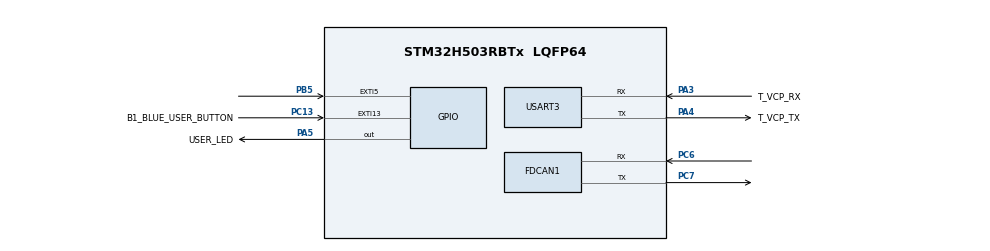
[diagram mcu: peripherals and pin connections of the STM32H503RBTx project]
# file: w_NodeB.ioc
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BOOTPATH.BootPathName=LEGACY
BOOTPATH.UserSelectedBootPath=LEGACY
FDCAN1.CalculateBaudRateNominal=500000
FDCAN1.CalculateTimeBitNominal=2000
FDCAN1.CalculateTimeQuantumNominal=125.0
FDCAN1.NominalPrescaler=25
FDCAN1.NominalTimeSeg1=13
FDCAN1.NominalTimeSeg2=2
Mcu.Family=STM32H5
Mcu.Name=STM32H503RBTx
Mcu.Package=LQFP64
NVIC.EXTI13_IRQn=true\:0\:0\:false\:false\:true\:true\:true\:true
NVIC.EXTI5_IRQn=true\:0\:0\:false\:false\:true\:true\:true\:true
NVIC.FDCAN1_IT0_IRQn=true\:0\:0\:false\:false\:true\:true\:true\:true
NVIC.PriorityGroup=NVIC_PRIORITYGROUP_4
NVIC.USART3_IRQn=true\:0\:0\:false\:false\:true\:true\:true\:true
PA3.GPIO_Label=T_VCP_RX
PA3.Mode=Asynchronous
PA3.Signal=USART3_RX
PA4.GPIO_Label=T_VCP_TX
PA4.Mode=Asynchronous
PA4.Signal=USART3_TX
PA5.GPIO_Label=USER_LED
PA5.Signal=GPIO_Output
PB5.Signal=GPXTI5
PC13.GPIO_Label=B1_BLUE_USER_BUTTON
PC13.Signal=GPXTI13
PC6.Mode=FDCAN_Activate
PC6.Signal=FDCAN1_RX
PC7.Mode=FDCAN_Activate
PC7.Signal=FDCAN1_TX
PH0-OSC_IN(PH0).Mode=HSE-External-Oscillator
PH0-OSC_IN(PH0).Signal=RCC_OSC_IN
PH1-OSC_OUT(PH1).Mode=HSE-External-Oscillator
PH1-OSC_OUT(PH1).Signal=RCC_OSC_OUT
ProjectManager.HeapSize=0x200
ProjectManager.StackSize=0x400
ProjectManager.TargetToolchain=STM32CubeIDE
RCC.ADCFreq_Value=200000000
RCC.AHBFreq_Value=200000000
RCC.APB1Freq_Value=200000000
RCC.APB1TimFreq_Value=200000000
RCC.APB2Freq_Value=200000000
RCC.APB2TimFreq_Value=200000000
RCC.APB3Freq_Value=200000000
RCC.CSI_VALUE=4000000
RCC.CortexFreq_Value=200000000
RCC.EPOD_VALUE=24000000
RCC.FDCANClockSelection=RCC_FDCANCLKSOURCE_PLL1Q
RCC.HCLKFreq_Value=200000000
RCC.HSE_VALUE=24000000
RCC.HSI48_VALUE=48000000
RCC.HSIDiv=RCC_HSI_DIV1
RCC.HSI_VALUE=64000000
RCC.LSE_VALUE=32768
RCC.LSIRC_VALUE=32000
RCC.PLLFRACN=0
RCC.PLLM=3
RCC.PLLN=50
RCC.PLLSourceVirtual=RCC_PLL1_SOURCE_HSE
RCC.SYSCLKFreq_VALUE=200000000
RCC.SYSCLKSource=RCC_SYSCLKSOURCE_PLLCLK
RCC.USBFreq_Value=48000000
RCC.VCOOutputFreq_Value=400000000
USART3.VirtualMode-Asynchronous=VM_ASYNC
VP_BOOTPATH_VS_BOOTPATH.Mode=BP_Activate
VP_CORTEX_M33_NS_VS_Hclk.Mode=Hclk_Mode
VP_MEMORYMAP_VS_MEMORYMAP.Mode=CurAppReg
VP_PWR_VS_DBSignals.Mode=DisableDeadBatterySignals
VP_PWR_VS_LPOM.Mode=PowerOptimisation
VP_PWR_VS_SECSignals.Mode=Security/Privilege
board=NUCLEO-H503RB

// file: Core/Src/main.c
#include "main.h"
#include <stdio.h>

FDCAN_HandleTypeDef hfdcan1;
UART_HandleTypeDef huart3;
static void MX_FDCAN1_Init(void);
void SetFilter(uint16_t ID ,uint16_t msk);
void Test_Priority();
void TX_Send_CAN();
void Print_CAN_Error();
void Check_CAN_ErrorCnt();
void Check_CAN_Protocol_Status();
/* declared variable -----------------------------------------------*/
volatile uint8_t counter = 0;
volatile uint8_t flag = 0;
volatile uint8_t tx_complete_flag = 0;
typedef struct{
	FDCAN_TxHeaderTypeDef   TxHeader;
	FDCAN_RxHeaderTypeDef   RxHeader;
	uint32_t msgID;
	uint8_t dataTx[8];
	uint8_t dataRx[8];
} CAN_SET;

CAN_SET CAN_Payload;

int main(void)
{
  /* MCU Configuration--------------------------------------------------------*/
   HAL_Init();
  /* Configure the system clock */
  SystemClock_Config();
  /* Initialize all configured peripherals */
  MX_GPIO_Init();
  MX_FDCAN1_Init();
  MX_USART3_UART_Init();

  //CAN_Payload.dataTx[0] = 0x0;
  for(uint8_t i = 0 ; i < 8 ;i++){
  	  CAN_Payload.dataTx[i] = 0xFF;
    }

  while (1)
  {
	  if (flag == 1){
		  HAL_Delay(1);
		  Print_CAN_Error();
		  Check_CAN_ErrorCnt();
		  Check_CAN_Protocol_Status();
		  flag = 0;
	  }
//	  if (tx_complete_flag == 1)
//	     {
//	         tx_complete_flag = 0;
//
//	         Print_CAN_Error();
//	         Check_CAN_ErrorCnt();
//	         Check_CAN_Protocol_Status();
//	     }
  }
}

static void MX_FDCAN1_Init(void)
{

  hfdcan1.Instance = FDCAN1;
  hfdcan1.Init.ClockDivider = FDCAN_CLOCK_DIV1;
  hfdcan1.Init.FrameFormat = FDCAN_FRAME_CLASSIC;
  hfdcan1.Init.Mode = FDCAN_MODE_NORMAL;
  hfdcan1.Init.AutoRetransmission = DISABLE;
  hfdcan1.Init.TransmitPause = DISABLE;
  hfdcan1.Init.ProtocolException = DISABLE;
  hfdcan1.Init.NominalPrescaler = 25;
  hfdcan1.Init.NominalSyncJumpWidth = 1;
  hfdcan1.Init.NominalTimeSeg1 = 13;
  hfdcan1.Init.NominalTimeSeg2 = 2;
  hfdcan1.Init.DataPrescaler = 1;
  hfdcan1.Init.DataSyncJumpWidth = 1;
  hfdcan1.Init.DataTimeSeg1 = 1;
  hfdcan1.Init.DataTimeSeg2 = 1;
  hfdcan1.Init.StdFiltersNbr = 1;
  hfdcan1.Init.ExtFiltersNbr = 0;
  hfdcan1.Init.TxFifoQueueMode = FDCAN_TX_FIFO_OPERATION;
  if (HAL_FDCAN_Init(&hfdcan1) != HAL_OK)
  {
    Error_Handler();
  }
  /* USER CODE BEGIN FDCAN1_Init 2 */
  if (HAL_FDCAN_Start(&hfdcan1) != HAL_OK) {
  	 /* Notification Error */
  	Error_Handler();
  }
  if (HAL_FDCAN_ActivateNotification(&hfdcan1, FDCAN_IT_RX_FIFO0_NEW_MESSAGE, 0) != HAL_OK)
  {
	/* Notification Error */
	Error_Handler();
  }
 // HAL_FDCAN_ActivateNotification(&hfdcan1, FDCAN_IT_TX_COMPLETE, 0);
  /* USER CODE END FDCAN1_Init 2 */
}

void Test_Ack(){
	CAN_Payload.msgID = 0x10F;
	//CAN_Payload.msgID = 0x000;
	TX_Send_CAN();
}

void TX_Send_CAN(){

    /* ----- Prepare CAN data --------------------------------------- */
    CAN_Payload.TxHeader.IdType = FDCAN_STANDARD_ID;
    CAN_Payload.TxHeader.Identifier = CAN_Payload.msgID; //CAN_Payload.msgID
    CAN_Payload.TxHeader.TxFrameType = FDCAN_DATA_FRAME;
    CAN_Payload.TxHeader.DataLength = FDCAN_DLC_BYTES_8;        // 8-byte payloaD
    CAN_Payload.TxHeader.ErrorStateIndicator = FDCAN_ESI_ACTIVE;
    CAN_Payload.TxHeader.BitRateSwitch = FDCAN_BRS_OFF;         // Disable BRS
    CAN_Payload.TxHeader.FDFormat = FDCAN_CLASSIC_CAN;          // Use Classical CAN frame
    CAN_Payload.TxHeader.TxEventFifoControl = FDCAN_NO_TX_EVENTS;
    CAN_Payload.TxHeader.MessageMarker = 0;

    CAN_Payload.dataTx[0] ^= 1;

    if (HAL_FDCAN_AddMessageToTxFifoQ(&hfdcan1, &CAN_Payload.TxHeader,CAN_Payload.dataTx)!= HAL_OK)
    {
      /*do not thing */
    }

}

void HAL_GPIO_EXTI_Falling_Callback(uint16_t GPIO_Pin){

	if(GPIO_Pin == GPIO_PIN_5) {
		flag = 1;
		GPIOA->ODR &= ~(1<<5);
	}

	if(GPIO_Pin == B1_BLUE_USER_BUTTON_Pin){
		Test_Ack();
		flag = 1;
		GPIOA->ODR |= (1<<5);
	}
}

void HAL_FDCAN_RxFifo0Callback(FDCAN_HandleTypeDef *hfdcan, uint32_t RxFifo0ITs)
{
	if((RxFifo0ITs & FDCAN_IT_RX_FIFO0_NEW_MESSAGE) != RESET)
	{
		/* Retreive Rx messages from RX FIFO0 */
		if (HAL_FDCAN_GetRxMessage(hfdcan, FDCAN_RX_FIFO0, &CAN_Payload.RxHeader,CAN_Payload.dataRx) != HAL_OK)
		{
			/* Reception Error */
			Error_Handler();
		}
		if (HAL_FDCAN_ActivateNotification(hfdcan, FDCAN_IT_RX_FIFO0_NEW_MESSAGE, 0) != HAL_OK)
		{
			/* Notification Error */
			Error_Handler();
		}
	}
	if(CAN_Payload.dataRx[0] == 0x1){
		HAL_GPIO_TogglePin(GPIOA, GPIO_PIN_5);
	}
}

void Print_CAN_Error(void) {
    uint32_t lec = (FDCAN1->PSR) & 0x7; /*Last error code*/

    switch (lec) {
        case 0b000:
            printf("No CAN error occurred\r\n");
            break;
        case 0b001:
            printf("Stuff error\r\n");
            break;
        case 0b010:
            printf("Form error\r\n");
            break;
        case 0b011:
            printf("Ack error\r\n");
            break;
        case 0b100:
            printf("Bit error ->Bit1 error:\r\n");
            break;
        case 0b101:
            printf("Bit error ->Bit0 error\r\n");
            break;
        case 0b110:
            printf("CRC error: CRC mismatch on received frame\r\n");
            break;
        case 0b111:
            printf("LEC unchanged: No event since last read\r\n"); /*When read lec it reset to 111*/
            break;
    }
}

void Check_CAN_ErrorCnt(void) {

    uint8_t TEC = FDCAN1->ECR & 0xFF;         /*Transmit Error Counter: bits [7:0]*/
    uint8_t REC = (FDCAN1->ECR >> 8) & 0x7F;  /* Receive Error Counter: bits [14:8]*/

    printf("Transmit Error Counter (TEC): %d\r\n", TEC);
    printf("Receive Error Counter (REC) : %d\r\n", REC); /*max 0-127*/

}

void Check_CAN_Protocol_Status(void){
  /*Bus-Off check*/
  if (FDCAN1->PSR & FDCAN_PSR_BO) {
        printf("CAN Status: BUS-OFF\r\n\n");
  }
  // Error Passive check
  else if (FDCAN1->PSR & FDCAN_PSR_EP) {
      printf("CAN Status: ERROR PASSIVE\r\n\n");
  }
  // Active mode
  else {
      printf("CAN Status: ERROR ACTIVE\r\n\n");
  }
}

int __io_putchar(int ch)
{
    HAL_UART_Transmit(&huart3, (uint8_t*)&ch, 1,1000);
    return ch;
}
/* USER CODE END 4 */
//void HAL_FDCAN_TxBufferCompleteCallback(FDCAN_HandleTypeDef *hfdcan, uint32_t BufferIndexes)
//{
//    if (hfdcan->Instance == FDCAN1)
//    {
//        tx_complete_flag = 1;
//    }
//}

void Error_Handler(void)
{
  __disable_irq();
  while (1)
  {
  }
}
